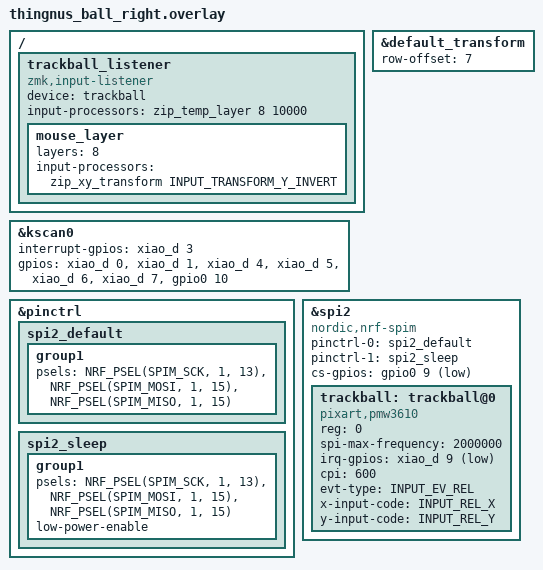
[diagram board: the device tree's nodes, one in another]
#include "thingnus_ball.dtsi"

&default_transform {
  row-offset = <7>;
};

/ {
    // pointing device
    trackball_listener {
        compatible = "zmk,input-listener";
        device = <&trackball>;
        input-processors = <&zip_temp_layer 8 10000>;

        mouse_layer {
          layers = <8>;

          input-processors = <&zip_xy_transform INPUT_TRANSFORM_Y_INVERT>;
        };
    };
};

&kscan0 {

  interrupt-gpios = <&xiao_d 3 (GPIO_ACTIVE_HIGH | GPIO_PULL_DOWN)>;
  
  gpios = <&xiao_d 0 (GPIO_ACTIVE_HIGH)>  // 0
        , <&xiao_d 1 (GPIO_ACTIVE_HIGH)>  // 1
        , <&xiao_d 4 (GPIO_ACTIVE_HIGH)>  // 2
        , <&xiao_d 5 (GPIO_ACTIVE_HIGH)>  // 3
        , <&xiao_d 6 (GPIO_ACTIVE_HIGH)>  // 4
        , <&xiao_d 7  (GPIO_ACTIVE_HIGH)>  // 5
        , <&gpio0 10  (GPIO_ACTIVE_HIGH)>  // 6
        ;
};

&pinctrl {
    spi2_default: spi2_default {
        group1 {
            psels = <NRF_PSEL(SPIM_SCK, 1, 13)>, //SCLK
                    <NRF_PSEL(SPIM_MOSI, 1, 15)>, //SDIO
                    <NRF_PSEL(SPIM_MISO, 1, 15)>; //SDIO
        };
    };

    spi2_sleep: spi2_sleep {
        group1 {
            psels = <NRF_PSEL(SPIM_SCK, 1, 13)>, //SCLK
                    <NRF_PSEL(SPIM_MOSI, 1, 15)>, //SDIO
                    <NRF_PSEL(SPIM_MISO, 1, 15)>; //SDIO
            low-power-enable;
        };
    };
};

&spi2 {
    status = "okay";
    compatible = "nordic,nrf-spim";
    pinctrl-0 = <&spi2_default>;
    pinctrl-1 = <&spi2_sleep>;
    pinctrl-names = "default", "sleep";
    cs-gpios = <&gpio0 9 GPIO_ACTIVE_LOW>; // NCS

    trackball: trackball@0 {
        status = "okay";
        compatible = "pixart,pmw3610";
        reg = <0>;
        spi-max-frequency = <2000000>;
        irq-gpios = <&xiao_d 9 (GPIO_ACTIVE_LOW | GPIO_PULL_UP)>; //MOT
        cpi = <600>;
        evt-type = <INPUT_EV_REL>;
        x-input-code = <INPUT_REL_X>;
        y-input-code = <INPUT_REL_Y>;
    };
};
